# evalsoc register map
Vendor: Nuclei; Series: Nuclei Evaluation SoC
CPU: Evalsoc, little endian
Registers are 32-bit, read-write, reset 0x0 unless marked. A register's access mark holds for its fields unless they carry their own. Offsets are from the block's base; [hi:lo] are bit positions; {n}, {i} and the like mark numbered series; 'fields as' and 'values as' point back to an identical list.

## PLIC — Address space of PLIC unit. The Platform-Level Interrupt Controller (PLIC) is used for Linux capable applications or symmetric multi-processor (SMP) applications.
Base 0x1C000000
{0x0+4i} SOURCE{i}_PRIORITY (i=0..127) — Source priority registers for interrupt source i.
  [31:0] PRIORITY — Priority for source i.
{0x1000+4i} PENDING{i} (i=0..3) — Interrupt pending bits for sources i*32 to i*32+31
  [31:0] PENDING — Pending bits for sources i*32 to i*32+31.
{0x2000+4i} M_INT_ENABLE{i} (i=0..3) — M-mode interrupt enables for Hart 0, source i*32 to i*32+31.
  [31:0] ENABLE — M-mode enable bits for sources i*32 to i*32+31.
{0x2080+4i} S_INT_ENABLE{i} (i=0..3) — S-mode interrupt enables for Hart 0, source i*32 to i*32+31
  [31:0] ENABLE — S-mode enable bits for sources i*32 to i*32+31.
0x200000 M_PRIORITY_THRESHOLD — M-mode priority threshold for Hart 0.
  [31:0] THRESHOLD — M-mode priority threshold.
0x200004 M_CLAIM_COMPLETE — M-mode claim/complete register for Hart 0.
  [31:0] CLAIM_COMPLETE — Read to claim highest priority pending interrupt, write to complete.
0x201000 S_PRIORITY_THRESHOLD — S-mode priority threshold for Hart 0.
  [31:0] THRESHOLD — S-mode priority threshold.
0x201004 S_CLAIM_COMPLETE — S-mode claim/complete register for Hart 0.
  fields as M_CLAIM_COMPLETE
0x3FFFFFC plic_srw_ctrl — Control S-mode can access PLIC registers or not. Only accessible by M-mode.
  [0] SRW — Control S-mode can read or write PLIC registers or not.<br>0: S-Mode can read/write all PLIC registers.<br>1: S-Mode can not read/write PLIC registers

## GPIO0 — General purpose input/output controller.
Base 0x10012000
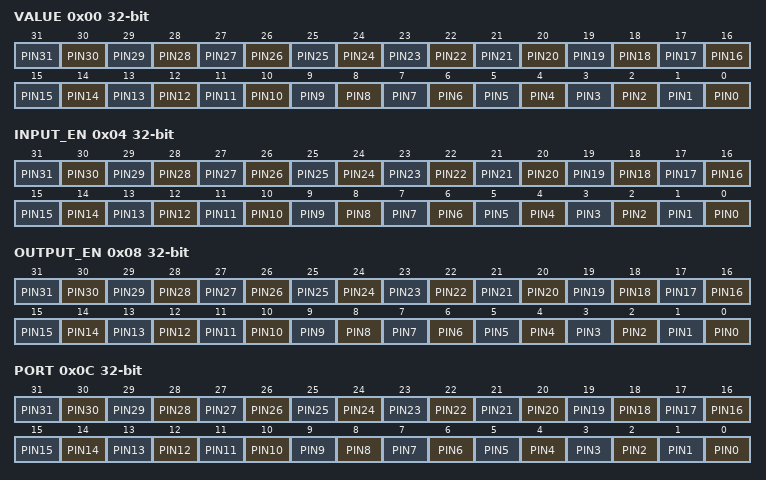
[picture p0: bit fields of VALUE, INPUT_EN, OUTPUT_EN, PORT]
0x00 VALUE — Pin value.
  [n] PIN{n} (n=0..31)
0x04 INPUT_EN — Pin input enable.
  [n] PIN{n} (n=0..31)
0x08 OUTPUT_EN — Pin output enable.
  [n] PIN{n} (n=0..31)
0x0C PORT — Output port value.
  [n] PIN{n} (n=0..31)
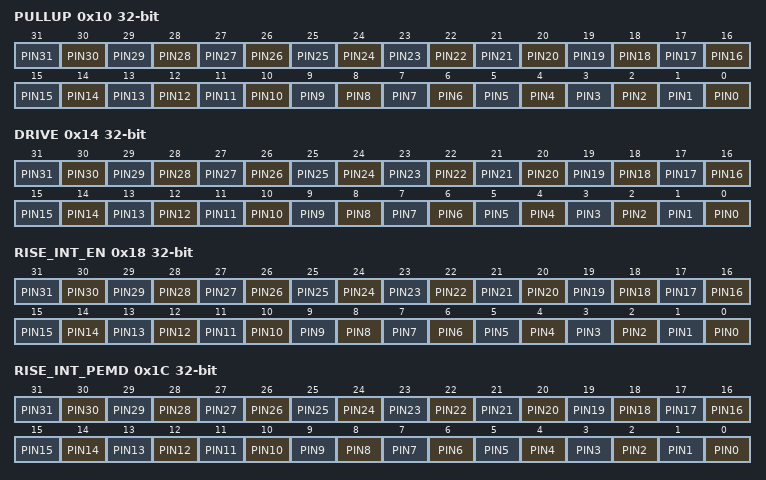
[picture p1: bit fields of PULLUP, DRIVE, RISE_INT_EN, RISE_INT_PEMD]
0x10 PULLUP — Internal Pull-Up enable.
  [n] PIN{n} (n=0..31)
0x14 DRIVE — Drive Strength.
  [n] PIN{n} (n=0..31)
0x18 RISE_INT_EN — Rise interrupt enable.
  [n] PIN{n} (n=0..31)
0x1C RISE_INT_PEMD — Rise interrupt pending.
  [n] PIN{n} (n=0..31)
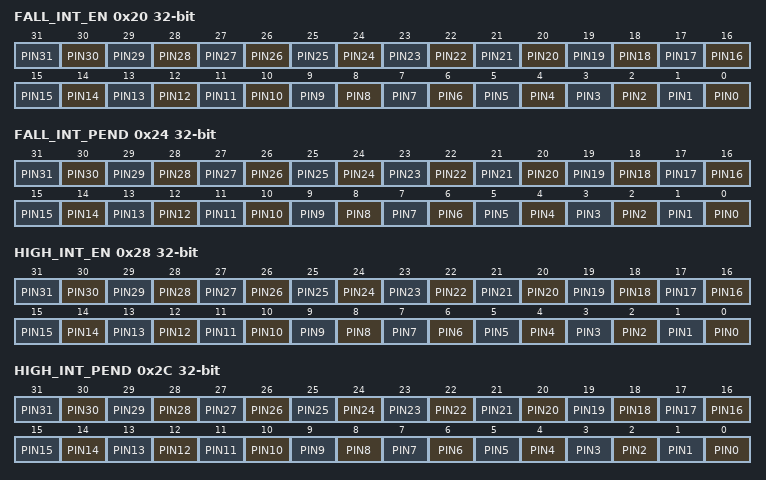
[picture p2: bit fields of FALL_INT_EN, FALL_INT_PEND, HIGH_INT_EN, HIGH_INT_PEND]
0x20 FALL_INT_EN — Fall interrupt enable.
  [n] PIN{n} (n=0..31)
0x24 FALL_INT_PEND — Fall interrupt pending.
  [n] PIN{n} (n=0..31)
0x28 HIGH_INT_EN — High interrupt enable.
  [n] PIN{n} (n=0..31)
0x2C HIGH_INT_PEND — High interrupt pending.
  [n] PIN{n} (n=0..31)
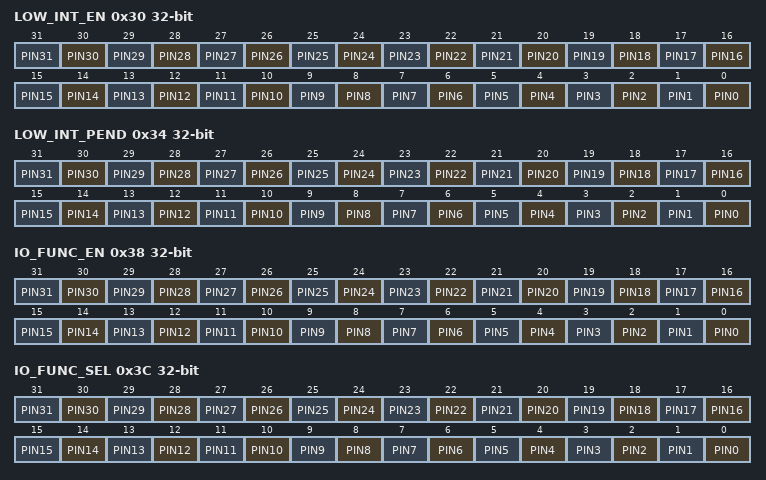
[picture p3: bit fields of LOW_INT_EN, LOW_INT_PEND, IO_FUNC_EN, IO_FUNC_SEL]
0x30 LOW_INT_EN — Low interrupt enable.
  [n] PIN{n} (n=0..31)
0x34 LOW_INT_PEND — Low interrupt pending.
  [n] PIN{n} (n=0..31)
0x38 IO_FUNC_EN — HW I/O function enable.
  [n] PIN{n} (n=0..31)
0x3C IO_FUNC_SEL — HW I/O function select.
  [n] PIN{n} (n=0..31)
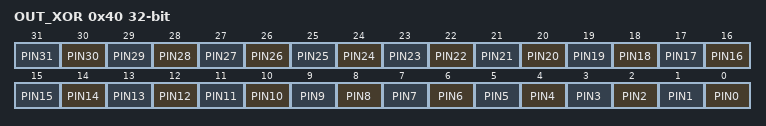
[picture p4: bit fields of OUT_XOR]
0x40 OUT_XOR — Output XOR (invert).
  [n] PIN{n} (n=0..31)

## QSPI0 — Serial Peripheral Interface.
Base 0x10014000
Same registers: QSPI1 0x10024000, QSPI2 0x10034000
0x00 SCKDIV — Serial Clock Divisor Register.
  [11:0] SCALE
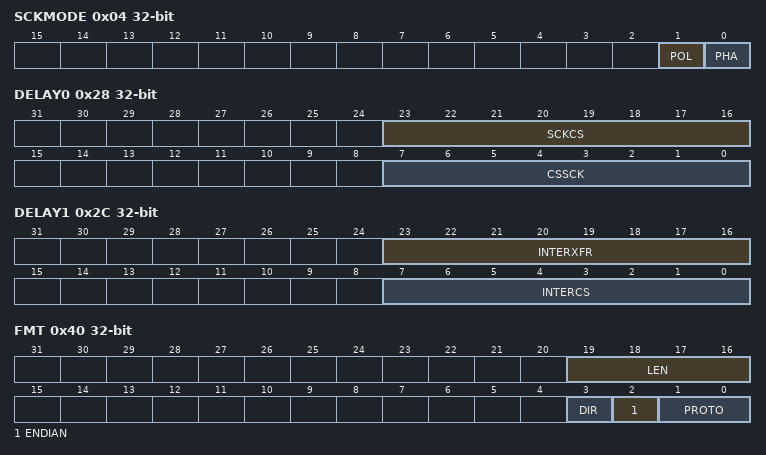
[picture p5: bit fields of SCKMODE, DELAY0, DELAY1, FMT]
0x04 SCKMODE — Serial Clock Mode Register.
  [1] POL — Serial Clock Polarity
    0=Inactive state of SCK is logical 0; 1=Inactive state of SCK is logical 1
  [0] PHA — Serial Clock Phase
    0=Data is sampled on the leading edge of SCK and shifted on the trailing edge of SCK; 1=Data is shifted on the leading edge of SCK and sampled on the trailing edge of SCK
0x10 CSID — Chip Select ID Register.
0x14 CSDEF — Chip Select Default Register.
0x18 CSMODE — Chip Select Mode Register.
  [1:0] MODE
    0=AUTO (Assert/de-assert CS at the beginning/end of each frame.); 2=HOLD (Keep CS continuously asserted after the initial frame.); 3=OFF (Disable hardware control of the CS pin.)
0x28 DELAY0 — Delay Control Register 0.
  [23:16] SCKCS, [7:0] CSSCK
0x2C DELAY1 — Delay Control Register 1.
  [23:16] INTERXFR, [7:0] INTERCS
0x40 FMT — Frame Format Register.
  [19:16] LEN
  [3] DIR
    0=RX (For dual and quad protocols, the DQ pins are tri-stated. For the single protocol, the DQ0 pin is driven with the transmit data as normal.); 1=TX (The receive FIFO is not populated.)
  [2] ENDIAN
    0=MSB_First (Tansmit most-significant bit first.); 1=LSB_First (Transmit least-significant bit first.)
  [1:0] PROTO
    0=Single (Data Pins: DQ0 (MOSI), DQ1 (MISO).); 1=Dual (Data Pins: DQ0, DQ1.); 2=Quad (Data Pins: DQ0, DQ1, DQ2, DQ3.)
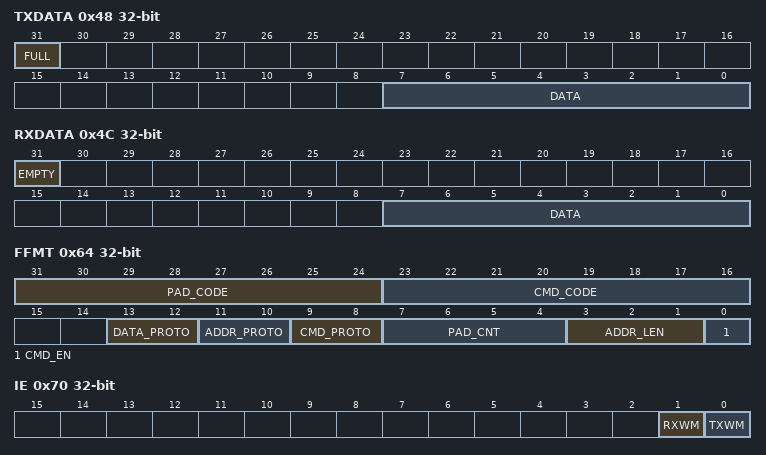
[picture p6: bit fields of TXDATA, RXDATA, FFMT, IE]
0x48 TXDATA — Transmit Data Register.
  [31] FULL, [7:0] DATA
0x4C RXDATA — Receive Data Register.
  [31] EMPTY, [7:0] DATA
0x50 TXMARK — Transmit Watermark Register.
  [2:0] TXMARK
0x54 RXMARK — Receive Watermark Register.
  [2:0] RXMARK
0x60 FCTRL — SPI Flash Interface Control Register.
  [0] ENABLE
0x64 FFMT — SPI Flash Instruction Format Register.
  [31:24] PAD_CODE, [23:16] CMD_CODE, [13:12] DATA_PROTO, [11:10] ADDR_PROTO, [9:8] CMD_PROTO, [7:4] PAD_CNT, [3:1] ADDR_LEN, [0] CMD_EN
0x70 IE — SPI Interrupt Enable Register.
  [1] RXWM, [0] TXWM
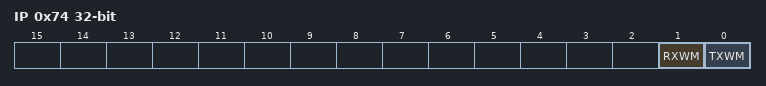
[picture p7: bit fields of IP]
0x74 IP — SPI Interrupt Pending Register.
  [1] RXWM, [0] TXWM

## UART0 — Universal Asynchronous Receiver/Transmitter.
Base 0x10013000
Same registers: UART1 0x10023000
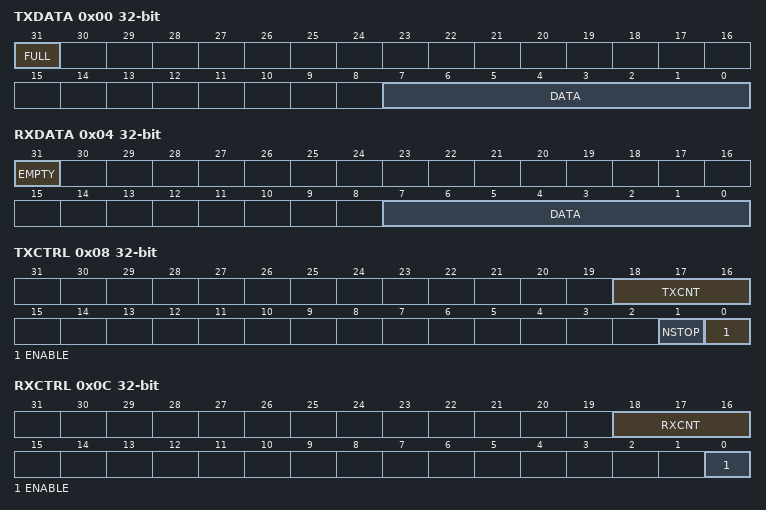
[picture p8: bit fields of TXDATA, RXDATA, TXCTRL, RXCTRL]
0x00 TXDATA — Transmit Data Register.
  [31] FULL, [7:0] DATA
0x04 RXDATA — Receive Data Register.
  [31] EMPTY, [7:0] DATA
0x08 TXCTRL — Transmit Control Register.
  [18:16] TXCNT, [1] NSTOP, [0] ENABLE
0x0C RXCTRL — Receive Control Register.
  [18:16] RXCNT, [0] ENABLE
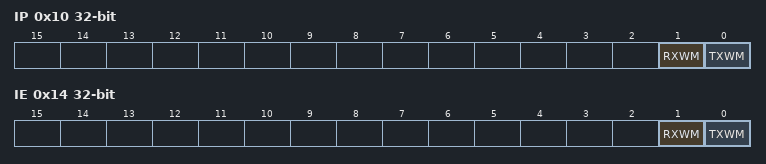
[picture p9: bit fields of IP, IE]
0x10 IP — Interrupt Pending Register.
  [1] RXWM, [0] TXWM
0x14 IE — Interrupt Enable Register.
  [1] RXWM, [0] TXWM
0x18 DIV — Baud Rate Divisor Register (BAUD = Fin / (DIV + 1)).
  [15:0] DIV
